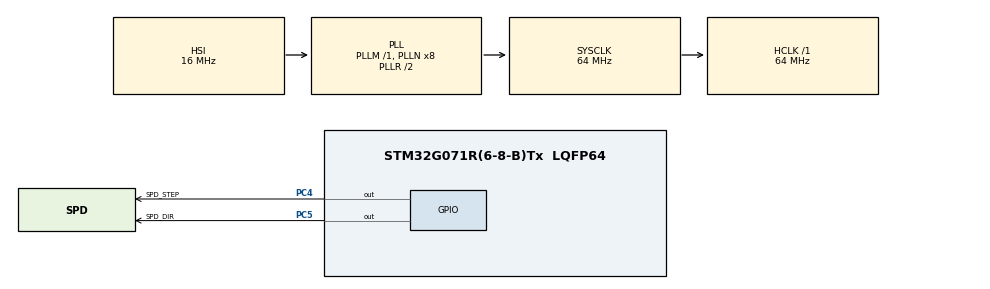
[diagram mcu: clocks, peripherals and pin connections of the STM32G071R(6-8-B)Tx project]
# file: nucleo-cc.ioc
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Mcu.Family=STM32G0
Mcu.Name=STM32G071R(6-8-B)Tx
Mcu.Package=LQFP64
PC4.GPIO_Label=SPD_STEP
PC4.GPIO_Speed=GPIO_SPEED_FREQ_VERY_HIGH
PC4.Signal=GPIO_Output
PC5.GPIO_Label=SPD_DIR
PC5.GPIO_ModeDefaultOutputPP=GPIO_MODE_OUTPUT_PP
PC5.GPIO_PuPd=GPIO_NOPULL
PC5.GPIO_Speed=GPIO_SPEED_FREQ_VERY_HIGH
PC5.Signal=GPIO_Output
ProjectManager.HeapSize=0x200
ProjectManager.StackSize=0x400
ProjectManager.TargetToolchain=STM32CubeIDE
RCC.ADCFreq_Value=64000000
RCC.AHBFreq_Value=64000000
RCC.CortexFreq_Value=64000000
RCC.EXTERNAL_CLOCK_VALUE=12288000
RCC.HCLKFreq_Value=64000000
RCC.HSE_VALUE=8000000
RCC.HSI_VALUE=16000000
RCC.SYSCLKFreq_VALUE=64000000
RCC.SYSCLKSource=RCC_SYSCLKSOURCE_PLLCLK
RCC.VCOOutputFreq_Value=128000000
board=NUCLEO-G071RB

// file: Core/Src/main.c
/* USER CODE BEGIN Header */
/**
  ******************************************************************************
  * @file           : main.c
  * @brief          : Main program body
  ******************************************************************************
  * @attention
  *
  * Copyright (c) 2024 STMicroelectronics.
  * All rights reserved.
  *
  * This software is licensed under terms that can be found in the LICENSE file
  * in the root directory of this software component.
  * If no LICENSE file comes with this software, it is provided AS-IS.
  *
  ******************************************************************************
  */
/* USER CODE END Header */
#include "main.h"

void SystemClock_Config(void);
static void MX_GPIO_Init(void);

/* USER CODE BEGIN 0 */

typedef enum {
	SPD_DIR_FORWARD = 0,
	SPD_DIR_BACKWARD,
	SPD_DIR_WAIT
} SPD_DIR_e;

typedef struct {

	struct {
		uint32_t currentPosition;
		uint32_t designatedPosition;
	} Position;

	SPD_DIR_e Direction;
} SPD_CL;

static SPD_CL Spd_Obj;

static const uint32_t spdTable[25] = {0, 97, 12, 225, 52, 20, 70, 180, 90, 143, 110, 2, 198, 200, 150, 210, 70, 18, 190, 10, 210, 76, 196, 15, 0};

void doStep() {
	HAL_Delay(4);
	HAL_GPIO_WritePin(SPD_STEP_GPIO_Port, SPD_STEP_Pin, 0);
	HAL_Delay(4);
	HAL_GPIO_WritePin(SPD_STEP_GPIO_Port, SPD_STEP_Pin, 1);
}

void moveTo() {
	if (Spd_Obj.Position.currentPosition
			< Spd_Obj.Position.designatedPosition) {
		if (Spd_Obj.Direction != SPD_DIR_FORWARD) {
			HAL_GPIO_WritePin(SPD_DIR_GPIO_Port, SPD_DIR_Pin, 1);
			Spd_Obj.Direction = SPD_DIR_FORWARD;
		}
		doStep();
		++Spd_Obj.Position.currentPosition;
	}
	if (Spd_Obj.Position.currentPosition
			> Spd_Obj.Position.designatedPosition) {
		if (Spd_Obj.Direction != SPD_DIR_BACKWARD) {
			HAL_GPIO_WritePin(SPD_DIR_GPIO_Port, SPD_DIR_Pin, 0);
			Spd_Obj.Direction = SPD_DIR_BACKWARD;
		}
		doStep();
		--Spd_Obj.Position.currentPosition;
	}

	if (Spd_Obj.Position.currentPosition == Spd_Obj.Position.designatedPosition)
	{
		Spd_Obj.Direction = SPD_DIR_WAIT;
	}

}

/* USER CODE END 0 */

int main(void)
{

  /* MCU Configuration--------------------------------------------------------*/

  /* Reset of all peripherals, Initializes the Flash interface and the Systick. */
  HAL_Init();

  /* Configure the system clock */
  SystemClock_Config();

  /* Initialize all configured peripherals */
  MX_GPIO_Init();
  /* USER CODE BEGIN 2 */
  Spd_Obj.Position.currentPosition = 400;
  Spd_Obj.Position.designatedPosition = 0;
  /* USER CODE END 2 */

  /* Infinite loop */
  /* USER CODE BEGIN WHILE */
  uint16_t pos = 0;
  uint32_t tickTime = 0;
  while (1)
  {
    /* USER CODE END WHILE */
	  //if(HAL_GetTick() - tickTime > 200)
	  if(Spd_Obj.Direction == SPD_DIR_WAIT)
	  {
		  if(pos > 220) {
			  pos = 0;
		  }
		 // tickTime = HAL_GetTick();
		  HAL_Delay(100);
		  ++pos;
	  }

	  Spd_Obj.Position.designatedPosition = pos;

	  moveTo();

  }
}

void SystemClock_Config(void)
{
  RCC_OscInitTypeDef RCC_OscInitStruct = {0};
  RCC_ClkInitTypeDef RCC_ClkInitStruct = {0};

  /** Configure the main internal regulator output voltage
  */
  HAL_PWREx_ControlVoltageScaling(PWR_REGULATOR_VOLTAGE_SCALE1);

  /** Initializes the RCC Oscillators according to the specified parameters
  * in the RCC_OscInitTypeDef structure.
  */
  RCC_OscInitStruct.OscillatorType = RCC_OSCILLATORTYPE_HSI;
  RCC_OscInitStruct.HSIState = RCC_HSI_ON;
  RCC_OscInitStruct.HSIDiv = RCC_HSI_DIV1;
  RCC_OscInitStruct.HSICalibrationValue = RCC_HSICALIBRATION_DEFAULT;
  RCC_OscInitStruct.PLL.PLLState = RCC_PLL_ON;
  RCC_OscInitStruct.PLL.PLLSource = RCC_PLLSOURCE_HSI;
  RCC_OscInitStruct.PLL.PLLM = RCC_PLLM_DIV1;
  RCC_OscInitStruct.PLL.PLLN = 8;
  RCC_OscInitStruct.PLL.PLLP = RCC_PLLP_DIV2;
  RCC_OscInitStruct.PLL.PLLQ = RCC_PLLQ_DIV2;
  RCC_OscInitStruct.PLL.PLLR = RCC_PLLR_DIV2;
  if (HAL_RCC_OscConfig(&RCC_OscInitStruct) != HAL_OK)
  {
    Error_Handler();
  }

  /** Initializes the CPU, AHB and APB buses clocks
  */
  RCC_ClkInitStruct.ClockType = RCC_CLOCKTYPE_HCLK|RCC_CLOCKTYPE_SYSCLK
                              |RCC_CLOCKTYPE_PCLK1;
  RCC_ClkInitStruct.SYSCLKSource = RCC_SYSCLKSOURCE_PLLCLK;
  RCC_ClkInitStruct.AHBCLKDivider = RCC_SYSCLK_DIV1;
  RCC_ClkInitStruct.APB1CLKDivider = RCC_HCLK_DIV1;

  if (HAL_RCC_ClockConfig(&RCC_ClkInitStruct, FLASH_LATENCY_2) != HAL_OK)
  {
    Error_Handler();
  }
}

static void MX_GPIO_Init(void)
{
  GPIO_InitTypeDef GPIO_InitStruct = {0};

  /* GPIO Ports Clock Enable */
  __HAL_RCC_GPIOC_CLK_ENABLE();

  /*Configure GPIO pin Output Level */
  HAL_GPIO_WritePin(GPIOC, SPD_STEP_Pin|SPD_DIR_Pin, GPIO_PIN_RESET);

  /*Configure GPIO pins : SPD_STEP_Pin SPD_DIR_Pin */
  GPIO_InitStruct.Pin = SPD_STEP_Pin|SPD_DIR_Pin;
  GPIO_InitStruct.Mode = GPIO_MODE_OUTPUT_PP;
  GPIO_InitStruct.Pull = GPIO_NOPULL;
  GPIO_InitStruct.Speed = GPIO_SPEED_FREQ_VERY_HIGH;
  HAL_GPIO_Init(GPIOC, &GPIO_InitStruct);

}

void Error_Handler(void)
{
  __disable_irq();
  while (1)
  {
  }
}
